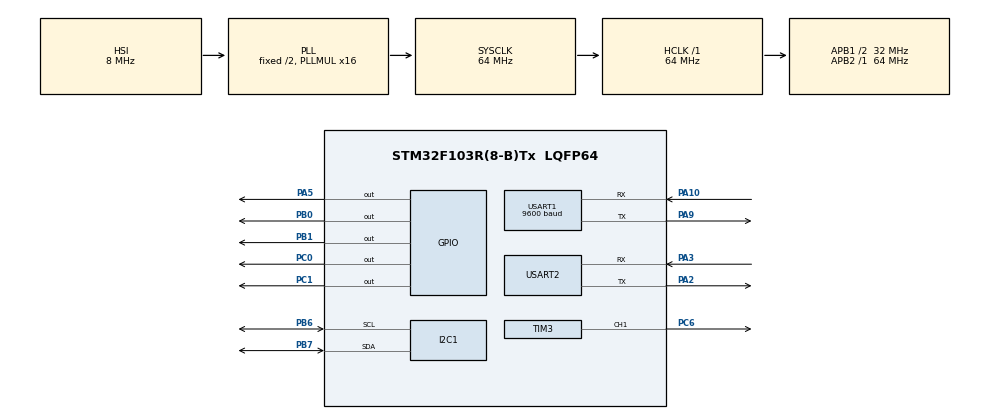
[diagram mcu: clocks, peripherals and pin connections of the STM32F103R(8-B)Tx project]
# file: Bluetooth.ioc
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Dma.Request0=USART1_RX
Dma.USART1_RX.0.Direction=DMA_PERIPH_TO_MEMORY
Dma.USART1_RX.0.Instance=DMA1_Channel5
Dma.USART1_RX.0.MemDataAlignment=DMA_MDATAALIGN_BYTE
Dma.USART1_RX.0.MemInc=DMA_MINC_ENABLE
Dma.USART1_RX.0.Mode=DMA_CIRCULAR
Dma.USART1_RX.0.PeriphDataAlignment=DMA_PDATAALIGN_BYTE
Dma.USART1_RX.0.PeriphInc=DMA_PINC_DISABLE
Dma.USART1_RX.0.Priority=DMA_PRIORITY_VERY_HIGH
I2C1.AddressingMode=I2C_ADDRESSINGMODE_7BIT
Mcu.Family=STM32F1
Mcu.Name=STM32F103R(8-B)Tx
Mcu.Package=LQFP64
NVIC.DMA1_Channel5_IRQn=true\:0\:0\:false\:false\:true\:false\:true
NVIC.PriorityGroup=NVIC_PRIORITYGROUP_4
NVIC.TIM4_IRQn=true\:0\:0\:false\:false\:true\:true\:true
NVIC.USART1_IRQn=true\:0\:0\:false\:false\:true\:true\:true
PA10.Mode=Asynchronous
PA10.Signal=USART1_RX
PA2.Mode=Asynchronous
PA2.Signal=USART2_TX
PA3.Mode=Asynchronous
PA3.Signal=USART2_RX
PA5.Signal=GPIO_Output
PA9.Mode=Asynchronous
PA9.Signal=USART1_TX
PB0.Signal=GPIO_Output
PB1.Signal=GPIO_Output
PB6.Mode=I2C
PB6.Signal=I2C1_SCL
PB7.Mode=I2C
PB7.Signal=I2C1_SDA
PC0.Signal=GPIO_Output
PC1.Signal=GPIO_Output
PC6.Signal=S_TIM3_CH1
ProjectManager.HeapSize=0x200
ProjectManager.StackSize=0x400
ProjectManager.TargetToolchain=STM32CubeIDE
RCC.ADCPresc=RCC_ADCPCLK2_DIV8
RCC.AHBFreq_Value=64000000
RCC.APB1CLKDivider=RCC_HCLK_DIV2
RCC.APB1Freq_Value=32000000
RCC.APB1TimFreq_Value=64000000
RCC.APB2Freq_Value=64000000
RCC.APB2TimFreq_Value=64000000
RCC.HCLKFreq_Value=64000000
RCC.PLLMUL=RCC_PLL_MUL16
RCC.SYSCLKFreq_VALUE=64000000
RCC.SYSCLKSource=RCC_SYSCLKSOURCE_PLLCLK
RCC.USBFreq_Value=64000000
SH.S_TIM3_CH1.0=TIM3_CH1,PWM Generation1 CH1
TIM3.AutoReloadPreload=TIM_AUTORELOAD_PRELOAD_ENABLE
TIM3.Channel-PWM\ Generation1\ CH1=TIM_CHANNEL_1
TIM3.Period=999
TIM3.Prescaler=63
TIM3.Pulse-PWM\ Generation1\ CH1=499
TIM4.AutoReloadPreload=TIM_AUTORELOAD_PRELOAD_ENABLE
TIM4.Period=499
TIM4.Prescaler=63000
USART1.BaudRate=9600
USART1.VirtualMode=VM_ASYNC
USART2.VirtualMode=VM_ASYNC
VP_SYS_VS_ND.Mode=No_Debug
VP_TIM3_VS_ClockSourceINT.Mode=Internal
VP_TIM4_VS_ClockSourceINT.Mode=Internal
board=custom

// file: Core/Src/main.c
/* USER CODE BEGIN Header */
/**
  ******************************************************************************
  * @file           : main.c
  * @brief          : Main program body
  ******************************************************************************
  * @attention
  *
  * <h2><center>&copy; Copyright (c) 2021 STMicroelectronics.
  * All rights reserved.</center></h2>
  *
  * This software component is licensed by ST under BSD 3-Clause license,
  * the "License"; You may not use this file except in compliance with the
  * License. You may obtain a copy of the License at:
  *                        opensource.org/licenses/BSD-3-Clause
  *
  ******************************************************************************
  */
/* USER CODE END Header */
#include "main.h"
#include "dma.h"
#include "i2c.h"
#include "tim.h"
#include "usart.h"
#include "gpio.h"

/* USER CODE BEGIN PM */
volatile uint16_t buf;
/* USER CODE END PM */

void SystemClock_Config(void);

/* USER CODE BEGIN 0 */

int Get_Temp() {
  int raw_temp = HAL_ADC_GetValue(&hadc1);
  float voltage = raw_temp * 330 / 1023; // Calculate temp based on raw reading
  return voltage;
}

/* USER CODE END 0 */

int main(void)
{

  /* MCU Configuration--------------------------------------------------------*/

  /* Reset of all peripherals, Initializes the Flash interface and the Systick. */
  HAL_Init();

  /* Configure the system clock */
  SystemClock_Config();

  /* Initialize all configured peripherals */
  MX_GPIO_Init();
  MX_USART1_UART_Init();
  MX_USART2_UART_Init();
  MX_TIM3_Init();
  MX_DMA_Init();
  MX_TIM4_Init();
  MX_I2C1_Init();

  /* Infinite loop */
  /* USER CODE BEGIN WHILE */

  HAL_ADCEx_Calibration_Start(&hadc1);

  char str[20];

  HAL_ADC_Start(&hadc1);

  char end[] = "\n\r";

  float voltage = 0;

  while (1)
  {
	  HAL_I2C_IsDeviceReady(hi2c, DevAddress, Trials, Timeout)
    /* USER CODE END WHILE */

  }
}

void SystemClock_Config(void)
{
  RCC_OscInitTypeDef RCC_OscInitStruct = {0};
  RCC_ClkInitTypeDef RCC_ClkInitStruct = {0};

  /** Initializes the RCC Oscillators according to the specified parameters
  * in the RCC_OscInitTypeDef structure.
  */
  RCC_OscInitStruct.OscillatorType = RCC_OSCILLATORTYPE_HSI;
  RCC_OscInitStruct.HSIState = RCC_HSI_ON;
  RCC_OscInitStruct.HSICalibrationValue = RCC_HSICALIBRATION_DEFAULT;
  RCC_OscInitStruct.PLL.PLLState = RCC_PLL_ON;
  RCC_OscInitStruct.PLL.PLLSource = RCC_PLLSOURCE_HSI_DIV2;
  RCC_OscInitStruct.PLL.PLLMUL = RCC_PLL_MUL16;
  if (HAL_RCC_OscConfig(&RCC_OscInitStruct) != HAL_OK)
  {
    Error_Handler();
  }
  /** Initializes the CPU, AHB and APB buses clocks
  */
  RCC_ClkInitStruct.ClockType = RCC_CLOCKTYPE_HCLK|RCC_CLOCKTYPE_SYSCLK
                              |RCC_CLOCKTYPE_PCLK1|RCC_CLOCKTYPE_PCLK2;
  RCC_ClkInitStruct.SYSCLKSource = RCC_SYSCLKSOURCE_PLLCLK;
  RCC_ClkInitStruct.AHBCLKDivider = RCC_SYSCLK_DIV1;
  RCC_ClkInitStruct.APB1CLKDivider = RCC_HCLK_DIV2;
  RCC_ClkInitStruct.APB2CLKDivider = RCC_HCLK_DIV1;

  if (HAL_RCC_ClockConfig(&RCC_ClkInitStruct, FLASH_LATENCY_2) != HAL_OK)
  {
    Error_Handler();
  }
}

void Error_Handler(void)
{
  __disable_irq();
  while (1)
  {
  }
}

/************************ (C) COPYRIGHT STMicroelectronics *****END OF FILE****/
